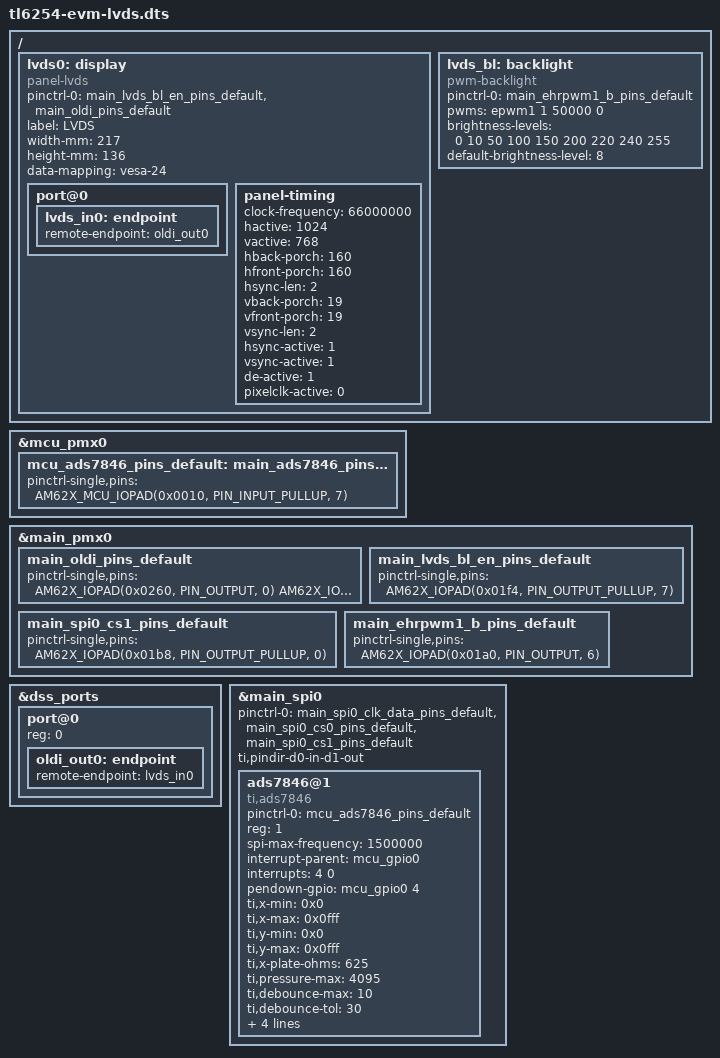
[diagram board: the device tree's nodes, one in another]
/*
 * Copyright (C) 2015 GuangZhou Tronlong co., LTD - http://www.tronlong.com
 *
 * This program is free software; you can redistribute it and/or modify
 * it under the terms of the GNU General Public License version 2 as
 * published by the Free Software Foundation.
 */

/dts-v1/;

#include "tl6254-evm.dts"

/ {
	/delete-node/ display;

	lvds0: display {
		compatible = "panel-lvds";
		pinctrl-names = "default";
		pinctrl-0 = <&main_lvds_bl_en_pins_default &main_oldi_pins_default>;

		label = "LVDS";
		width-mm = <217>;
		height-mm = <136>;
		data-mapping = "vesa-24";

		port@0 {
			lvds_in0: endpoint {
				remote-endpoint = <&oldi_out0>;
			};
		};
	};

	/delete-node/ backlight;

	lvds_bl: backlight {
                compatible = "pwm-backlight";
                pinctrl-names = "default";
                pinctrl-0 = <&main_ehrpwm1_b_pins_default>;

                pwms = <&epwm1 1 50000 0>;

                brightness-levels = <0 10 50 100 150 200 220 240 255>;
                default-brightness-level = <8>;
	};
};

&mcu_pmx0 {
	mcu_ads7846_pins_default: main_ads7846_pins_default {
		pinctrl-single,pins = <
			AM62X_MCU_IOPAD(0x0010, PIN_INPUT_PULLUP, 7) /* (C9) MCU_SPI0_D1.MCU_GPIO0_4 */
		>;
	};
};

&main_pmx0 {
	main_oldi_pins_default: main_oldi_pins_default {
		pinctrl-single,pins = <
			AM62X_IOPAD(0x0260, PIN_OUTPUT, 0) /* (AA5) OLDI0_A0N */
			AM62X_IOPAD(0x025c, PIN_OUTPUT, 0) /* (Y6) OLDI0_A0P */
			AM62X_IOPAD(0x0268, PIN_OUTPUT, 0) /* (AD3) OLDI0_A1N */
			AM62X_IOPAD(0x0264, PIN_OUTPUT, 0) /* (AB4) OLDI0_A1P */
			AM62X_IOPAD(0x0270, PIN_OUTPUT, 0) /* (Y8) OLDI0_A2N */
			AM62X_IOPAD(0x026c, PIN_OUTPUT, 0) /* (AA8) OLDI0_A2P */
			AM62X_IOPAD(0x0278, PIN_OUTPUT, 0) /* (AB6) OLDI0_A3N */
			AM62X_IOPAD(0x0274, PIN_OUTPUT, 0) /* (AA7) OLDI0_A3P */
			AM62X_IOPAD(0x0280, PIN_OUTPUT, 0) /* (AC6) OLDI0_A4N */
			AM62X_IOPAD(0x027c, PIN_OUTPUT, 0) /* (AC5) OLDI0_A4P */
			AM62X_IOPAD(0x0288, PIN_OUTPUT, 0) /* (AE5) OLDI0_A5N */
			AM62X_IOPAD(0x0284, PIN_OUTPUT, 0) /* (AD6) OLDI0_A5P */
			AM62X_IOPAD(0x0290, PIN_OUTPUT, 0) /* (AE6) OLDI0_A6N */
			AM62X_IOPAD(0x028c, PIN_OUTPUT, 0) /* (AD7) OLDI0_A6P */
			AM62X_IOPAD(0x0298, PIN_OUTPUT, 0) /* (AD8) OLDI0_A7N */
			AM62X_IOPAD(0x0294, PIN_OUTPUT, 0) /* (AE7) OLDI0_A7P */
			AM62X_IOPAD(0x02a0, PIN_OUTPUT, 0) /* (AD4) OLDI0_CLK0N */
			AM62X_IOPAD(0x029c, PIN_OUTPUT, 0) /* (AE3) OLDI0_CLK0P */
			AM62X_IOPAD(0x02a8, PIN_OUTPUT, 0) /* (AE4) OLDI0_CLK1N */
			AM62X_IOPAD(0x02a4, PIN_OUTPUT, 0) /* (AD5) OLDI0_CLK1P */
		>;
	};

	main_lvds_bl_en_pins_default: main_lvds_bl_en_pins_default {
		pinctrl-single,pins = <
			AM62X_IOPAD(0x01f4, PIN_OUTPUT_PULLUP, 7) /* (D16) EXTINTn.GPIO1_31 */
		>;
	};

	main_spi0_cs1_pins_default: main_spi0_cs1_pins_default {
                pinctrl-single,pins = <
                        AM62X_IOPAD(0x01b8, PIN_OUTPUT_PULLUP, 0) /* (C13) SPI0_CS1 */
                >;
        };

	main_ehrpwm1_b_pins_default: main_ehrpwm1_b_pins_default {
		pinctrl-single,pins = <
			AM62X_IOPAD(0x01a0, PIN_OUTPUT, 6) /* (E18) MCASP0_AXR0.EHRPWM1_B */
		>;
	};
};

&lvds0 {
        panel-timing {
		clock-frequency = <66000000>;
		hactive = <1024>;
		vactive = <768>;
		hback-porch = <160>;
		hfront-porch = <160>;
		hsync-len = <2>;
		vback-porch = <19>;
		vfront-porch = <19>;
		vsync-len = <2>;
		hsync-active = <1>;
		vsync-active = <1>;
		de-active = <1>;
		pixelclk-active = <0>;
        };
};

&dss_ports {
	#address-cells = <1>;
	#size-cells = <0>;

	/delete-node/ port@1;

	/* VP1: LVDS Output (OLDI TX 0) */
	port@0 {
		reg = <0>;
		oldi_out0: endpoint {
			remote-endpoint = <&lvds_in0>;
		};
	};
};

&main_spi0 {
        status = "okay";
        pinctrl-names = "default";
        pinctrl-0 = <&main_spi0_clk_data_pins_default &main_spi0_cs0_pins_default &main_spi0_cs1_pins_default>;
        ti,pindir-d0-in-d1-out;

        ads7846@1 {
                compatible = "ti,ads7846";
                pinctrl-names = "default";
                pinctrl-0 = <&mcu_ads7846_pins_default>;

                reg = <1>;                      /* CS1 */
                spi-max-frequency = <1500000>;

                interrupt-parent = <&mcu_gpio0>;
                interrupts = <4 0>;            /* gpio0_4 */
                pendown-gpio = <&mcu_gpio0 4 0>;

                ti,x-min = /bits/ 16 <0x0>;
                ti,x-max = /bits/ 16 <0x0fff>;
                ti,y-min = /bits/ 16 <0x0>;
                ti,y-max = /bits/ 16 <0x0fff>;

                ti,x-plate-ohms = /bits/ 16 <625>;
                ti,pressure-max = /bits/ 16 <4095>;

                ti,debounce-max = /bits/ 16 <10>;
                ti,debounce-tol = /bits/ 16 <30>;
                ti,debounce-rep = /bits/ 16 <1>;

                ti,settle-delay-usec = /bits/ 16 <150>;
                ti,keep-vref-on = <1>;

                linux,wakeup;
        };
};
